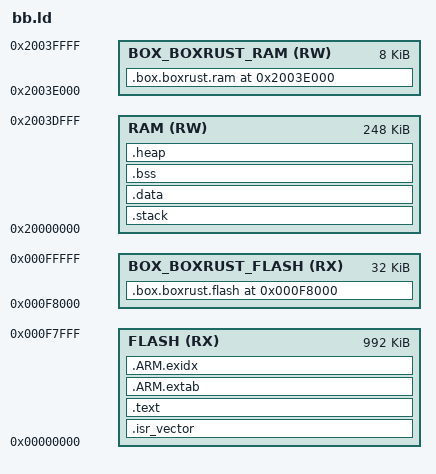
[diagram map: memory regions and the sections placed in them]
/***** AUTOGENERATED *****/

/* box calls */
__box_boxrust_rawinit = 0x1e000000 + 1*4 + 1*2 + 1;
__box_boxrust_raw_boxrust_add2 = 0x1e000000 + 3*4 + 1*2 + 1;
__box_boxrust_raw_boxrust_fib = 0x1e000000 + 5*4 + 1*2 + 1;
__box_boxrust_raw_boxrust_fib_alloc = 0x1e000000 + 7*4 + 0*2 + 1;
__box_boxrust_raw_boxrust_fib_next = 0x1e000000 + 9*4 + 1*2 + 1;
__box_boxrust_raw_boxrust_hello = 0x1e000000 + 11*4 + 1*2 + 1;
__box_boxrust_raw_boxrust_qsort = 0x1e000000 + 13*4 + 1*2 + 1;
__box_boxrust_raw_boxrust_qsort_alloc = 0x1e000000 + 15*4 + 0*2 + 1;
__box_boxrust_raw_boxrust_qsort_partition = 0x1e000000 + 17*4 + 1*2 + 1;

ENTRY(__box_reset_handler)

/* overridable constants */
__stack_min      = DEFINED(__stack_min) ? __stack_min : 0x00000800;
__heap_min       = DEFINED(__heap_min) ? __heap_min : 0x00000800;

MEMORY {
    FLASH            (RX ) : ORIGIN = 0x00000000, LENGTH = 0x000f8000
    BOX_BOXRUST_FLASH (RX ) : ORIGIN = 0x000f8000, LENGTH = 0x00008000
    RAM              (RW ) : ORIGIN = 0x20000000, LENGTH = 0x0003e000
    BOX_BOXRUST_RAM  (RW ) : ORIGIN = 0x2003e000, LENGTH = 0x00002000
}

SECTIONS {
    /* FLASH sections */
    . = ORIGIN(FLASH);
    . = ALIGN(4);
    __isr_vector_start = .;
    .isr_vector . : {
        KEEP(*(.isr_vector))
        . = __isr_vector_start + 0x400;
    } > FLASH
    . = ALIGN(4);
    __isr_vector_end = .;

    . = ALIGN(4);
    __text_start = .;
    .text . : {
        *(.text*)
        *(.rodata*)
        *(.glue_7*)
        *(.glue_7t*)
        *(.eh_frame*)

        KEEP(*(SORT_NONE(.init)))
        KEEP(*(SORT_NONE(.init*)))
        KEEP(*(SORT_NONE(.fini)))
        KEEP(*(SORT_NONE(.fini*)))

        . = ALIGN(4);
        PROVIDE_HIDDEN(__preinit_array_start = .);
        KEEP(*(SORT(.preinit_array)))
        PROVIDE_HIDDEN(__preinit_array_end = .);

        . = ALIGN(4);
        PROVIDE_HIDDEN(__init_array_start = .);
        KEEP(*(SORT(.init_array.*)))
        PROVIDE_HIDDEN(__init_array_end = .);

        . = ALIGN(4);
        PROVIDE_HIDDEN(__fini_array_start = .);
        KEEP(*(SORT(.fini_array.*)))
        PROVIDE_HIDDEN(__fini_array_end = .);

        KEEP(*crtbegin.o(.ctors))
        KEEP(*crtbegin?.o(.ctors))
        KEEP(*(EXCLUDE_FILE(*crtend?.o *crtend.o) .ctors))
        KEEP(*(SORT(.ctors.*)))

        KEEP(*crtbegin.o(.dtors))
        KEEP(*crtbegin?.o(.dtors))
        KEEP(*(EXCLUDE_FILE(*crtend?.o *crtend.o) .dtors))
        KEEP(*(SORT(.dtors.*)))
    } > FLASH
    . = ALIGN(4);
    __text_end = .;

    __extab_start = .;
    .ARM.extab : {
        *(.ARM.extab* .gnu.linkonce.armextab.*)
    } > FLASH
    __extab_end = .;

    __exidx_start = .;
    .ARM.exidx : {
        *(.ARM.exidx* .gnu.linkonce.armexidx.*)
    } > FLASH
    __exidx_end = .;

    . = ALIGN(4);
    __data_init_start = .;

    /* BOX_BOXRUST_FLASH sections */
    . = ORIGIN(BOX_BOXRUST_FLASH);
    __box_boxrust_flash_start = .;
    .box.boxrust.flash . : {
        KEEP(*(.box.boxrust.flash*))
    } > BOX_BOXRUST_FLASH
    . = ORIGIN(BOX_BOXRUST_FLASH) + LENGTH(BOX_BOXRUST_FLASH);
    __box_boxrust_flash_end = .;

    __box_boxrust_jumptable = __box_boxrust_flash_start;

    /* RAM sections */
    . = ORIGIN(RAM);
    . = ALIGN(4);
    __stack_start = .;
    .stack . (NOLOAD) : {
        . = .;
    } > RAM
    . += __stack_min;
    . = ALIGN(4);
    __stack_end = .;

    . = ALIGN(4);
    __data_start = .;
    .data . : AT(__data_init_start) {
        *(.data*)
    } > RAM
    . = ALIGN(4);
    __data_end = .;

    __data_init_end = LOADADDR(.data) + SIZEOF(.data);
    ASSERT(__data_init_end <= ORIGIN(FLASH) + LENGTH(FLASH),
        "Not enough memory in FLASH for data init")

    . = ALIGN(4);
    __bss_start = .;
    __bss_start__ = .;
    .bss . (NOLOAD) : {
        *(.bss*)
        *(COMMON)
    } > RAM
    . = ALIGN(4);
    __bss_end = .;
    __bss_end__ = .;

    . = ALIGN(4);
    __heap_start = .;
    __end__ = .;
    PROVIDE(end = .);
    .heap . (NOLOAD) : {
        . = .;
    } > RAM
    . = ORIGIN(RAM) + LENGTH(RAM);
    . = ALIGN(4);
    __heap_end = .;
    __heap_limit = .;

    ASSERT(__heap_end - __heap_start > __heap_min,
        "Not enough memory in RAM for heap")

    /* BOX_BOXRUST_RAM sections */
    . = ORIGIN(BOX_BOXRUST_RAM);
    __box_boxrust_ram_start = .;
    .box.boxrust.ram . (NOLOAD): {
        KEEP(*(.box.boxrust.ram*))
    } > BOX_BOXRUST_RAM
    . = ORIGIN(BOX_BOXRUST_RAM) + LENGTH(BOX_BOXRUST_RAM);
    __box_boxrust_ram_end = .;
}

